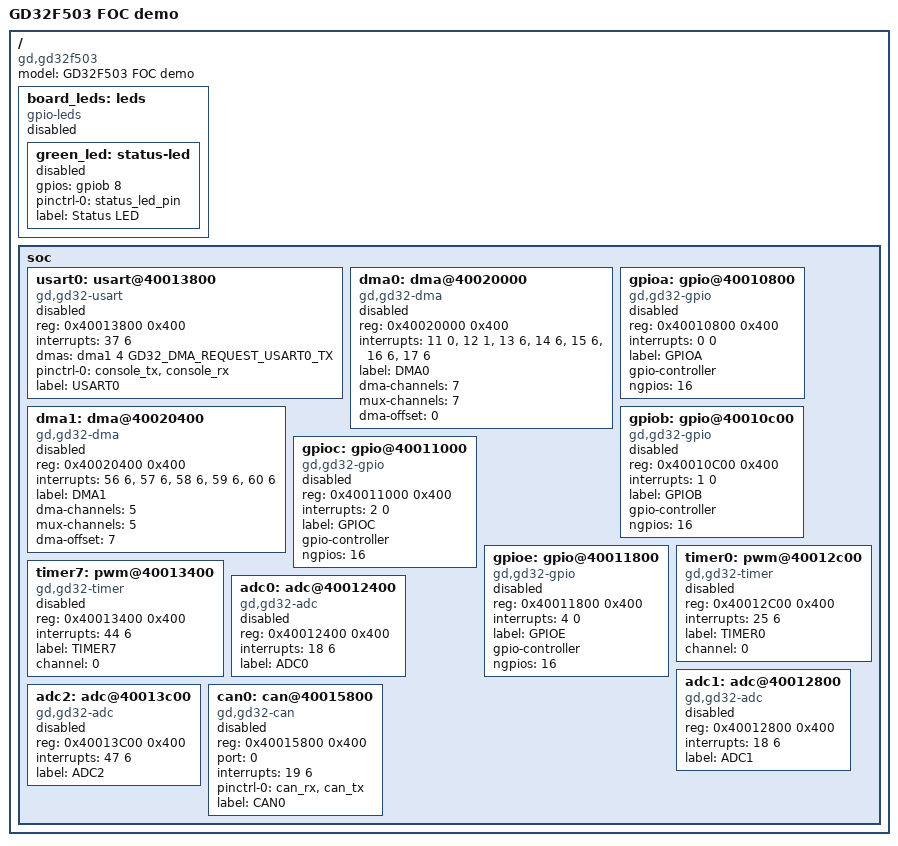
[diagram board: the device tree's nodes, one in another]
/dts-v1/;
#include <arm/gd/gd32f50x.dtsi>
#include <dt-bindings/dma/gd32_dma.h>
#include <dt-bindings/gpio/gpio.h>
#include <dt-bindings/pinctrl/gd32-pinctrl.h>
/ {
    compatible = "gd,gd32f503";
    model = "GD32F503 FOC demo";
    board_leds: leds {
        compatible = "gpio-leds";
        status = "disabled";
        green_led: status-led {
            status = "disabled";
            gpios = <&gpiob 8 GPIO_ACTIVE_HIGH>;
            pinctrl-0 = <&status_led_pin>;
            pinctrl-names = "default";
            label = "Status LED";
        };
    };
    soc {
        usart0: usart@40013800 {
            status = "disabled";
            compatible = "gd,gd32-usart";
            reg = <0x40013800 0x400>;
            interrupts = <37 6>;
            interrupt-names = "global";
            dmas = <&dma1 4 GD32_DMA_REQUEST_USART0_TX>;
            dma-names = "tx";
            pinctrl-0 = <&console_tx &console_rx>;
            pinctrl-names = "default";
            label = "USART0";
        };
        dma0: dma@40020000 {
            status = "disabled";
            compatible = "gd,gd32-dma";
            reg = <0x40020000 0x400>;
            interrupts = <11 0>, <12 1>, <13 6>, <14 6>, <15 6>, <16 6>, <17 6>;
            label = "DMA0";
            dma-channels = <7>;
            mux-channels = <7>;
            dma-offset = <0>;
            #dma-cells = <2>;
        };
        dma1: dma@40020400 {
            status = "disabled";
            compatible = "gd,gd32-dma";
            reg = <0x40020400 0x400>;
            interrupts = <56 6>, <57 6>, <58 6>, <59 6>, <60 6>;
            label = "DMA1";
            dma-channels = <5>;
            mux-channels = <5>;
            dma-offset = <7>;
            #dma-cells = <2>;
        };
        gpioa: gpio@40010800 {
            status = "disabled";
            compatible = "gd,gd32-gpio";
            reg = <0x40010800 0x400>;
            interrupts = <0 0>;
            label = "GPIOA";
            gpio-controller;
            #gpio-cells = <2>;
            ngpios = <16>;
        };
        gpiob: gpio@40010c00 {
            status = "disabled";
            compatible = "gd,gd32-gpio";
            reg = <0x40010C00 0x400>;
            interrupts = <1 0>;
            label = "GPIOB";
            gpio-controller;
            #gpio-cells = <2>;
            ngpios = <16>;
        };
        gpioc: gpio@40011000 {
            status = "disabled";
            compatible = "gd,gd32-gpio";
            reg = <0x40011000 0x400>;
            interrupts = <2 0>;
            label = "GPIOC";
            gpio-controller;
            #gpio-cells = <2>;
            ngpios = <16>;
        };
        gpioe: gpio@40011800 {
            status = "disabled";
            compatible = "gd,gd32-gpio";
            reg = <0x40011800 0x400>;
            interrupts = <4 0>;
            label = "GPIOE";
            gpio-controller;
            #gpio-cells = <2>;
            ngpios = <16>;
        };
        timer0: pwm@40012c00 {
            status = "disabled";
            compatible = "gd,gd32-timer";
            reg = <0x40012C00 0x400>;
            interrupts = <25 6>;
            interrupt-names = "update";
            label = "TIMER0";
            #pwm-cells = <3>;
            channel = <0>;
        };
        timer7: pwm@40013400 {
            status = "disabled";
            compatible = "gd,gd32-timer";
            reg = <0x40013400 0x400>;
            interrupts = <44 6>;
            interrupt-names = "update";
            label = "TIMER7";
            #pwm-cells = <3>;
            channel = <0>;
        };
        adc0: adc@40012400 {
            status = "disabled";
            compatible = "gd,gd32-adc";
            reg = <0x40012400 0x400>;
            interrupts = <18 6>;
            interrupt-names = "global";
            label = "ADC0";
            #io-channel-cells = <1>;
        };
        adc1: adc@40012800 {
            status = "disabled";
            compatible = "gd,gd32-adc";
            reg = <0x40012800 0x400>;
            interrupts = <18 6>;
            interrupt-names = "global";
            label = "ADC1";
            #io-channel-cells = <1>;
        };
        adc2: adc@40013c00 {
            status = "disabled";
            compatible = "gd,gd32-adc";
            reg = <0x40013C00 0x400>;
            interrupts = <47 6>;
            interrupt-names = "global";
            label = "ADC2";
            #io-channel-cells = <1>;
        };
        can0: can@40015800 {
            status = "disabled";
            compatible = "gd,gd32-can";
            reg = <0x40015800 0x400>;
            port = <0>;
            interrupts = <19 6>;
            pinctrl-0 = <&can_rx &can_tx>;
            pinctrl-names = "default";
            label = "CAN0";
        };
    };
};
#include "pinctrl.dtsi"
